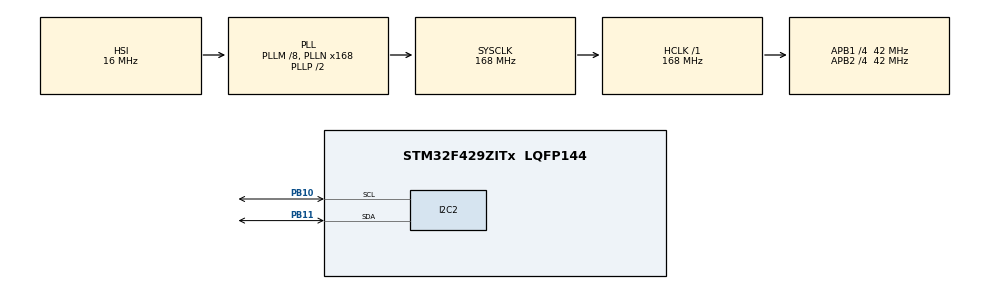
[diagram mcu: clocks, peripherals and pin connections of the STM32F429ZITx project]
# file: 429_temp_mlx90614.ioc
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Mcu.Family=STM32F4
RCC.CortexFreq_Value=168000000
PB10.Mode=I2C
RCC.SYSCLKSourceVirtual=RCC_SYSCLKSOURCE_PLLCLK
RCC.APB1CLKDivider=RCC_HCLK_DIV4
PB11.Signal=I2C2_SDA
RCC.SYSCLKSource=RCC_SYSCLKSOURCE_PLLCLK
ProjectManager.StackSize=0x400
PB11.Mode=I2C
ProjectManager.TargetToolchain=STM32CubeIDE
RCC.HCLKFreq_Value=168000000
RCC.APB2TimFreq_Value=84000000
RCC.USBFreq_Value=48000000
RCC.LSE_VALUE=32768
RCC.AHBFreq_Value=168000000
PB10.Signal=I2C2_SCL
RCC.HSE_VALUE=8000000
board=NUCLEO-F429ZI
RCC.VCOOutputFreq_Value=336000000
RCC.PLLMUL=RCC_PLL_MUL9
RCC.APB2Freq_Value=42000000
RCC.PRESCALERUSB=RCC_USBCLKSOURCE_PLL_DIV1_5
Mcu.Name=STM32F429ZITx
RCC.APB2TimCLKDivider=2
RCC.48MHZClocksFreq_Value=48000000
RCC.SYSCLKFreq_VALUE=168000000
Mcu.Package=LQFP144
ProjectManager.HeapSize=0x200
RCC.HSI_VALUE=16000000
RCC.PLLQ=7
NVIC.PriorityGroup=NVIC_PRIORITYGROUP_4
RCC.APB2CLKDivider=RCC_HCLK_DIV4
RCC.PLLM=8
RCC.PLLN=168
RCC.APB1TimFreq_Value=84000000
RCC.APB1Freq_Value=42000000
I2C2.I2C_Mode=I2C_Standard

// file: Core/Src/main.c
/* USER CODE BEGIN Header */
/**
  ******************************************************************************
  * @file           : main.c
  * @brief          : Main program body
  ******************************************************************************
  * @attention
  *
  * <h2><center>&copy; Copyright (c) 2021 STMicroelectronics.
  * All rights reserved.</center></h2>
  *
  * This software component is licensed by ST under BSD 3-Clause license,
  * the "License"; You may not use this file except in compliance with the
  * License. You may obtain a copy of the License at:
  *                        opensource.org/licenses/BSD-3-Clause
  *
  ******************************************************************************
  */
/* USER CODE END Header */
#include "main.h"

/* USER CODE BEGIN Includes */
#include "mlx90614.h"
/* USER CODE END Includes */

I2C_HandleTypeDef hi2c2;

void SystemClock_Config(void);
static void MX_GPIO_Init(void);
static void MX_I2C2_Init(void);

int main(void)
{

  /* MCU Configuration--------------------------------------------------------*/

  /* Reset of all peripherals, Initializes the Flash interface and the Systick. */
  HAL_Init();

  /* Configure the system clock */
  SystemClock_Config();

  /* Initialize all configured peripherals */
  MX_GPIO_Init();
  MX_I2C2_Init();
  /* USER CODE BEGIN 2 */

  float temp_obj1, temp_obj2, temp_amb;

  //HAL_Delay(1000);

  //MLX90614_ScanDevices();
  MLX90614_ReadReg(MLX90614_DEFAULT_SA, MLX90614_TOMIN, MLX90614_DBG_ON);
    MLX90614_ReadReg(MLX90614_DEFAULT_SA, MLX90614_TOMAX, MLX90614_DBG_ON);
    MLX90614_ReadReg(MLX90614_DEFAULT_SA, MLX90614_PWMCTRL, MLX90614_DBG_ON);
    MLX90614_ReadReg(MLX90614_DEFAULT_SA, MLX90614_TARANGE, MLX90614_DBG_ON);
    MLX90614_ReadReg(MLX90614_DEFAULT_SA, MLX90614_EMISSIVITY, MLX90614_DBG_ON);
    MLX90614_ReadReg(MLX90614_DEFAULT_SA, MLX90614_CFG1, MLX90614_DBG_ON);
    MLX90614_ReadReg(MLX90614_DEFAULT_SA, MLX90614_SA, MLX90614_DBG_ON);
    MLX90614_ReadReg(MLX90614_DEFAULT_SA, MLX90614_ID1, MLX90614_DBG_ON);
    MLX90614_ReadReg(MLX90614_DEFAULT_SA, MLX90614_ID2, MLX90614_DBG_ON);
    MLX90614_ReadReg(MLX90614_DEFAULT_SA, MLX90614_ID3, MLX90614_DBG_ON);
    MLX90614_ReadReg(MLX90614_DEFAULT_SA, MLX90614_ID4, MLX90614_DBG_ON);

    MLX90614_WriteReg(MLX90614_DEFAULT_SA, MLX90614_CFG1, 0xB7C0);

      MLX90614_ReadReg(MLX90614_DEFAULT_SA, MLX90614_CFG1, MLX90614_DBG_ON);

      MLX90614_WriteReg(MLX90614_DEFAULT_SA, MLX90614_PWMCTRL, 0x1405);

      MLX90614_ReadReg(MLX90614_DEFAULT_SA, MLX90614_PWMCTRL, MLX90614_DBG_ON);

  /* USER CODE END 2 */

  /* Infinite loop */
  while (1)
  {

    /* USER CODE BEGIN 3 */
	  temp_obj1 = MLX90614_ReadTemp(MLX90614_DEFAULT_SA, MLX90614_TOBJ1);
	  	  HAL_Delay(500);
	  	  temp_obj2 = MLX90614_ReadTemp(MLX90614_DEFAULT_SA, MLX90614_TOBJ2);;
	  	  HAL_Delay(500);
	  	  temp_amb = MLX90614_ReadTemp(MLX90614_DEFAULT_SA, MLX90614_TAMB);;
	  	  HAL_Delay(500);
  }
  /* USER CODE END 3 */
}

void SystemClock_Config(void)
{
  RCC_OscInitTypeDef RCC_OscInitStruct = {0};
  RCC_ClkInitTypeDef RCC_ClkInitStruct = {0};

  /** Configure the main internal regulator output voltage
  */
  __HAL_RCC_PWR_CLK_ENABLE();
  __HAL_PWR_VOLTAGESCALING_CONFIG(PWR_REGULATOR_VOLTAGE_SCALE1);
  /** Initializes the RCC Oscillators according to the specified parameters
  * in the RCC_OscInitTypeDef structure.
  */
  RCC_OscInitStruct.OscillatorType = RCC_OSCILLATORTYPE_HSI;
  RCC_OscInitStruct.HSIState = RCC_HSI_ON;
  RCC_OscInitStruct.HSICalibrationValue = RCC_HSICALIBRATION_DEFAULT;
  RCC_OscInitStruct.PLL.PLLState = RCC_PLL_ON;
  RCC_OscInitStruct.PLL.PLLSource = RCC_PLLSOURCE_HSI;
  RCC_OscInitStruct.PLL.PLLM = 8;
  RCC_OscInitStruct.PLL.PLLN = 168;
  RCC_OscInitStruct.PLL.PLLP = RCC_PLLP_DIV2;
  RCC_OscInitStruct.PLL.PLLQ = 7;
  if (HAL_RCC_OscConfig(&RCC_OscInitStruct) != HAL_OK)
  {
    Error_Handler();
  }
  /** Initializes the CPU, AHB and APB buses clocks
  */
  RCC_ClkInitStruct.ClockType = RCC_CLOCKTYPE_HCLK|RCC_CLOCKTYPE_SYSCLK
                              |RCC_CLOCKTYPE_PCLK1|RCC_CLOCKTYPE_PCLK2;
  RCC_ClkInitStruct.SYSCLKSource = RCC_SYSCLKSOURCE_PLLCLK;
  RCC_ClkInitStruct.AHBCLKDivider = RCC_SYSCLK_DIV1;
  RCC_ClkInitStruct.APB1CLKDivider = RCC_HCLK_DIV4;
  RCC_ClkInitStruct.APB2CLKDivider = RCC_HCLK_DIV4;

  if (HAL_RCC_ClockConfig(&RCC_ClkInitStruct, FLASH_LATENCY_5) != HAL_OK)
  {
    Error_Handler();
  }
}

static void MX_I2C2_Init(void)
{

  hi2c2.Instance = I2C2;
  hi2c2.Init.ClockSpeed = 100000;
  hi2c2.Init.DutyCycle = I2C_DUTYCYCLE_2;
  hi2c2.Init.OwnAddress1 = 0;
  hi2c2.Init.AddressingMode = I2C_ADDRESSINGMODE_7BIT;
  hi2c2.Init.DualAddressMode = I2C_DUALADDRESS_DISABLE;
  hi2c2.Init.OwnAddress2 = 0;
  hi2c2.Init.GeneralCallMode = I2C_GENERALCALL_DISABLE;
  hi2c2.Init.NoStretchMode = I2C_NOSTRETCH_DISABLE;
  if (HAL_I2C_Init(&hi2c2) != HAL_OK)
  {
    Error_Handler();
  }
  /** Configure Analogue filter
  */
  if (HAL_I2CEx_ConfigAnalogFilter(&hi2c2, I2C_ANALOGFILTER_ENABLE) != HAL_OK)
  {
    Error_Handler();
  }
  /** Configure Digital filter
  */
  if (HAL_I2CEx_ConfigDigitalFilter(&hi2c2, 0) != HAL_OK)
  {
    Error_Handler();
  }

}

static void MX_GPIO_Init(void)
{

  /* GPIO Ports Clock Enable */
  __HAL_RCC_GPIOB_CLK_ENABLE();

}

void Error_Handler(void)
{
  __disable_irq();
  while (1)
  {
  }
}

/************************ (C) COPYRIGHT STMicroelectronics *****END OF FILE****/
